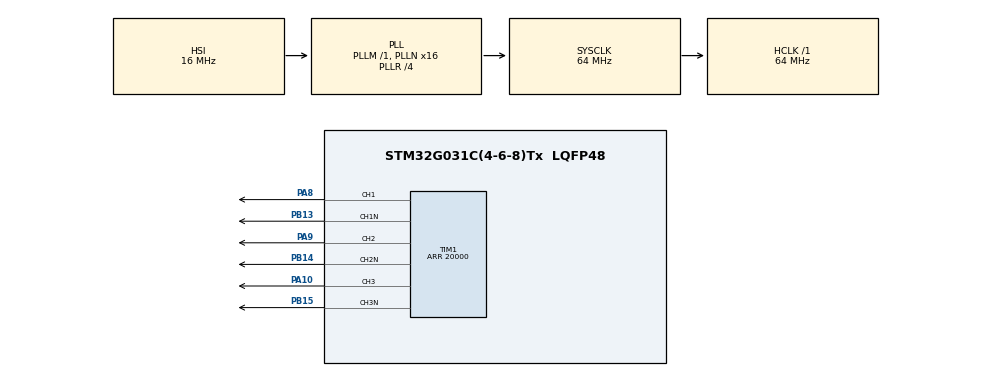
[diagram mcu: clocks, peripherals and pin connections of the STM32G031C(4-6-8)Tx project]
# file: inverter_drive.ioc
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Mcu.Family=STM32G0
Mcu.Name=STM32G031C(4-6-8)Tx
Mcu.Package=LQFP48
PA10.Signal=S_TIM1_CH3
PA8.Signal=S_TIM1_CH1
PA9.Signal=S_TIM1_CH2
PB13.Mode=PWM Generation1 CH1 CH1N
PB13.Signal=TIM1_CH1N
PB14.Mode=PWM Generation2 CH2 CH2N
PB14.Signal=TIM1_CH2N
PB15.Mode=PWM Generation3 CH3 CH3N
PB15.Signal=TIM1_CH3N
ProjectManager.HeapSize=0x200
ProjectManager.StackSize=0x400
ProjectManager.TargetToolchain=STM32CubeIDE
RCC.ADCFreq_Value=64000000
RCC.AHBFreq_Value=64000000
RCC.CortexFreq_Value=64000000
RCC.EXTERNAL_CLOCK_VALUE=12288000
RCC.HCLKFreq_Value=64000000
RCC.HSE_VALUE=8000000
RCC.HSI_VALUE=16000000
RCC.LSE_VALUE=32768
RCC.PLLN=16
RCC.PLLR=RCC_PLLR_DIV4
RCC.SYSCLKFreq_VALUE=64000000
RCC.SYSCLKSource=RCC_SYSCLKSOURCE_PLLCLK
RCC.TIM1CLockSelectionVirtual=RCC_TIM1CLKSOURCE_PLL
RCC.VCOOutputFreq_Value=256000000
SH.S_TIM1_CH1.0=TIM1_CH1,PWM Generation1 CH1 CH1N
SH.S_TIM1_CH2.0=TIM1_CH2,PWM Generation2 CH2 CH2N
SH.S_TIM1_CH3.0=TIM1_CH3,PWM Generation3 CH3 CH3N
TIM1.AutoReloadPreload=TIM_AUTORELOAD_PRELOAD_ENABLE
TIM1.Channel-PWM\ Generation1\ CH1\ CH1N=TIM_CHANNEL_1
TIM1.Channel-PWM\ Generation2\ CH2\ CH2N=TIM_CHANNEL_2
TIM1.Channel-PWM\ Generation3\ CH3\ CH3N=TIM_CHANNEL_3
TIM1.ClockDivision=TIM_CLOCKDIVISION_DIV2
TIM1.CounterMode=TIM_COUNTERMODE_CENTERALIGNED2
TIM1.DeadTime=255
TIM1.LockLevel=TIM_LOCKLEVEL_1
TIM1.OCFastMode_PWM-PWM\ Generation1\ CH1\ CH1N=TIM_OCFAST_ENABLE
TIM1.OCFastMode_PWM-PWM\ Generation2\ CH2\ CH2N=TIM_OCFAST_ENABLE
TIM1.OCFastMode_PWM-PWM\ Generation3\ CH3\ CH3N=TIM_OCFAST_ENABLE
TIM1.Period=20000
TIM1.Pulse-PWM\ Generation1\ CH1\ CH1N=1000
board=custom

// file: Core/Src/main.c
/* USER CODE BEGIN Header */
/**
  ******************************************************************************
  * @file           : main.c
  * @brief          : Main program body
  ******************************************************************************
  * @attention
  *
  * Copyright (c) 2026 STMicroelectronics.
  * All rights reserved.
  *
  * This software is licensed under terms that can be found in the LICENSE file
  * in the root directory of this software component.
  * If no LICENSE file comes with this software, it is provided AS-IS.
  *
  ******************************************************************************
  */
/* USER CODE END Header */
#include "main.h"

/* USER CODE BEGIN Includes */
#include "kernel.h"

/* USER CODE END Includes */

TIM_HandleTypeDef htim1;

void SystemClock_Config(void);
static void MX_GPIO_Init(void);
static void MX_TIM1_Init(void);

int main(void)
{

  /* MCU Configuration--------------------------------------------------------*/

  /* Reset of all peripherals, Initializes the Flash interface and the Systick. */
  HAL_Init();

  /* Configure the system clock */
  SystemClock_Config();

  /* Initialize all configured peripherals */
  MX_GPIO_Init();
  MX_TIM1_Init();
  /* USER CODE BEGIN 2 */
  STM32Kernel_Main();
  /* USER CODE END 2 */

  /* Infinite loop */
  while (1)
  {

  }
}

void SystemClock_Config(void)
{
  RCC_OscInitTypeDef RCC_OscInitStruct = {0};
  RCC_ClkInitTypeDef RCC_ClkInitStruct = {0};

  /** Configure the main internal regulator output voltage
  */
  HAL_PWREx_ControlVoltageScaling(PWR_REGULATOR_VOLTAGE_SCALE1);

  /** Initializes the RCC Oscillators according to the specified parameters
  * in the RCC_OscInitTypeDef structure.
  */
  RCC_OscInitStruct.OscillatorType = RCC_OSCILLATORTYPE_HSI;
  RCC_OscInitStruct.HSIState = RCC_HSI_ON;
  RCC_OscInitStruct.HSIDiv = RCC_HSI_DIV1;
  RCC_OscInitStruct.HSICalibrationValue = RCC_HSICALIBRATION_DEFAULT;
  RCC_OscInitStruct.PLL.PLLState = RCC_PLL_ON;
  RCC_OscInitStruct.PLL.PLLSource = RCC_PLLSOURCE_HSI;
  RCC_OscInitStruct.PLL.PLLM = RCC_PLLM_DIV1;
  RCC_OscInitStruct.PLL.PLLN = 16;
  RCC_OscInitStruct.PLL.PLLP = RCC_PLLP_DIV2;
  RCC_OscInitStruct.PLL.PLLQ = RCC_PLLQ_DIV2;
  RCC_OscInitStruct.PLL.PLLR = RCC_PLLR_DIV4;
  if (HAL_RCC_OscConfig(&RCC_OscInitStruct) != HAL_OK)
  {
    Error_Handler();
  }

  /** Initializes the CPU, AHB and APB buses clocks
  */
  RCC_ClkInitStruct.ClockType = RCC_CLOCKTYPE_HCLK|RCC_CLOCKTYPE_SYSCLK
                              |RCC_CLOCKTYPE_PCLK1;
  RCC_ClkInitStruct.SYSCLKSource = RCC_SYSCLKSOURCE_PLLCLK;
  RCC_ClkInitStruct.AHBCLKDivider = RCC_SYSCLK_DIV1;
  RCC_ClkInitStruct.APB1CLKDivider = RCC_HCLK_DIV1;

  if (HAL_RCC_ClockConfig(&RCC_ClkInitStruct, FLASH_LATENCY_2) != HAL_OK)
  {
    Error_Handler();
  }
}

static void MX_TIM1_Init(void)
{

  TIM_MasterConfigTypeDef sMasterConfig = {0};
  TIM_OC_InitTypeDef sConfigOC = {0};
  TIM_BreakDeadTimeConfigTypeDef sBreakDeadTimeConfig = {0};

  htim1.Instance = TIM1;
  htim1.Init.Prescaler = 0;
  htim1.Init.CounterMode = TIM_COUNTERMODE_CENTERALIGNED2;
  htim1.Init.Period = 20000;
  htim1.Init.ClockDivision = TIM_CLOCKDIVISION_DIV2;
  htim1.Init.RepetitionCounter = 0;
  htim1.Init.AutoReloadPreload = TIM_AUTORELOAD_PRELOAD_ENABLE;
  if (HAL_TIM_PWM_Init(&htim1) != HAL_OK)
  {
    Error_Handler();
  }
  sMasterConfig.MasterOutputTrigger = TIM_TRGO_RESET;
  sMasterConfig.MasterOutputTrigger2 = TIM_TRGO2_RESET;
  sMasterConfig.MasterSlaveMode = TIM_MASTERSLAVEMODE_DISABLE;
  if (HAL_TIMEx_MasterConfigSynchronization(&htim1, &sMasterConfig) != HAL_OK)
  {
    Error_Handler();
  }
  sConfigOC.OCMode = TIM_OCMODE_PWM1;
  sConfigOC.Pulse = 1000;
  sConfigOC.OCPolarity = TIM_OCPOLARITY_HIGH;
  sConfigOC.OCNPolarity = TIM_OCNPOLARITY_HIGH;
  sConfigOC.OCFastMode = TIM_OCFAST_ENABLE;
  sConfigOC.OCIdleState = TIM_OCIDLESTATE_RESET;
  sConfigOC.OCNIdleState = TIM_OCNIDLESTATE_RESET;
  if (HAL_TIM_PWM_ConfigChannel(&htim1, &sConfigOC, TIM_CHANNEL_1) != HAL_OK)
  {
    Error_Handler();
  }
  sConfigOC.Pulse = 0;
  if (HAL_TIM_PWM_ConfigChannel(&htim1, &sConfigOC, TIM_CHANNEL_2) != HAL_OK)
  {
    Error_Handler();
  }
  if (HAL_TIM_PWM_ConfigChannel(&htim1, &sConfigOC, TIM_CHANNEL_3) != HAL_OK)
  {
    Error_Handler();
  }
  sBreakDeadTimeConfig.OffStateRunMode = TIM_OSSR_DISABLE;
  sBreakDeadTimeConfig.OffStateIDLEMode = TIM_OSSI_DISABLE;
  sBreakDeadTimeConfig.LockLevel = TIM_LOCKLEVEL_1;
  sBreakDeadTimeConfig.DeadTime = 255;
  sBreakDeadTimeConfig.BreakState = TIM_BREAK_DISABLE;
  sBreakDeadTimeConfig.BreakPolarity = TIM_BREAKPOLARITY_HIGH;
  sBreakDeadTimeConfig.BreakFilter = 0;
  sBreakDeadTimeConfig.BreakAFMode = TIM_BREAK_AFMODE_INPUT;
  sBreakDeadTimeConfig.Break2State = TIM_BREAK2_DISABLE;
  sBreakDeadTimeConfig.Break2Polarity = TIM_BREAK2POLARITY_HIGH;
  sBreakDeadTimeConfig.Break2Filter = 0;
  sBreakDeadTimeConfig.Break2AFMode = TIM_BREAK_AFMODE_INPUT;
  sBreakDeadTimeConfig.AutomaticOutput = TIM_AUTOMATICOUTPUT_DISABLE;
  if (HAL_TIMEx_ConfigBreakDeadTime(&htim1, &sBreakDeadTimeConfig) != HAL_OK)
  {
    Error_Handler();
  }
  HAL_TIM_MspPostInit(&htim1);

}

static void MX_GPIO_Init(void)
{
  GPIO_InitTypeDef GPIO_InitStruct = {0};

  /* GPIO Ports Clock Enable */
  __HAL_RCC_GPIOB_CLK_ENABLE();
  __HAL_RCC_GPIOA_CLK_ENABLE();

  /*Configure GPIO pin Output Level */
  HAL_GPIO_WritePin(GPIOA, GPIO_PIN_11, GPIO_PIN_SET);

  /*Configure GPIO pin : PA11 */
  GPIO_InitStruct.Pin = GPIO_PIN_11;
  GPIO_InitStruct.Mode = GPIO_MODE_OUTPUT_PP;
  GPIO_InitStruct.Pull = GPIO_NOPULL;
  GPIO_InitStruct.Speed = GPIO_SPEED_FREQ_LOW;
  HAL_GPIO_Init(GPIOA, &GPIO_InitStruct);

}

void Error_Handler(void)
{
  __disable_irq();
  while (1)
  {
  }
}
